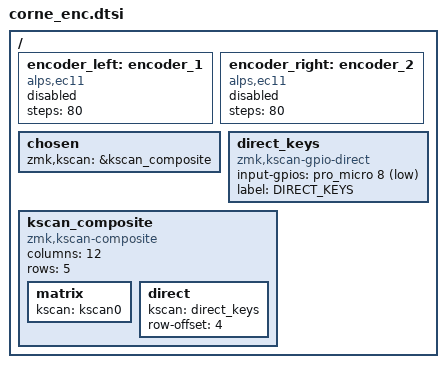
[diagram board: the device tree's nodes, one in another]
/ {
    // Define skeleton for the left encoder
    encoder_left: encoder_1 {
        compatible = "alps,ec11";
        steps = <80>;
        status = "disabled";
    };

    // Define skeleton for the right encoder
    encoder_right: encoder_2 {
        compatible = "alps,ec11";
        steps = <80>;
        status = "disabled";
    };

    chosen {
        zmk,kscan = &kscan_composite;
    };

        direct_keys: direct_keys {
            compatible = "zmk,kscan-gpio-direct";
            input-gpios = <&pro_micro 8 (GPIO_ACTIVE_LOW | GPIO_PULL_UP)>;
            label = "DIRECT_KEYS";
        };
        
    kscan_composite: kscan_composite {
        compatible = "zmk,kscan-composite";
        columns = <12>;
        rows = <5>;
        matrix {
            kscan = <&kscan0>;
        };
        direct {
            kscan = <&direct_keys>;
            row-offset = <4>;
        };
    };
};
